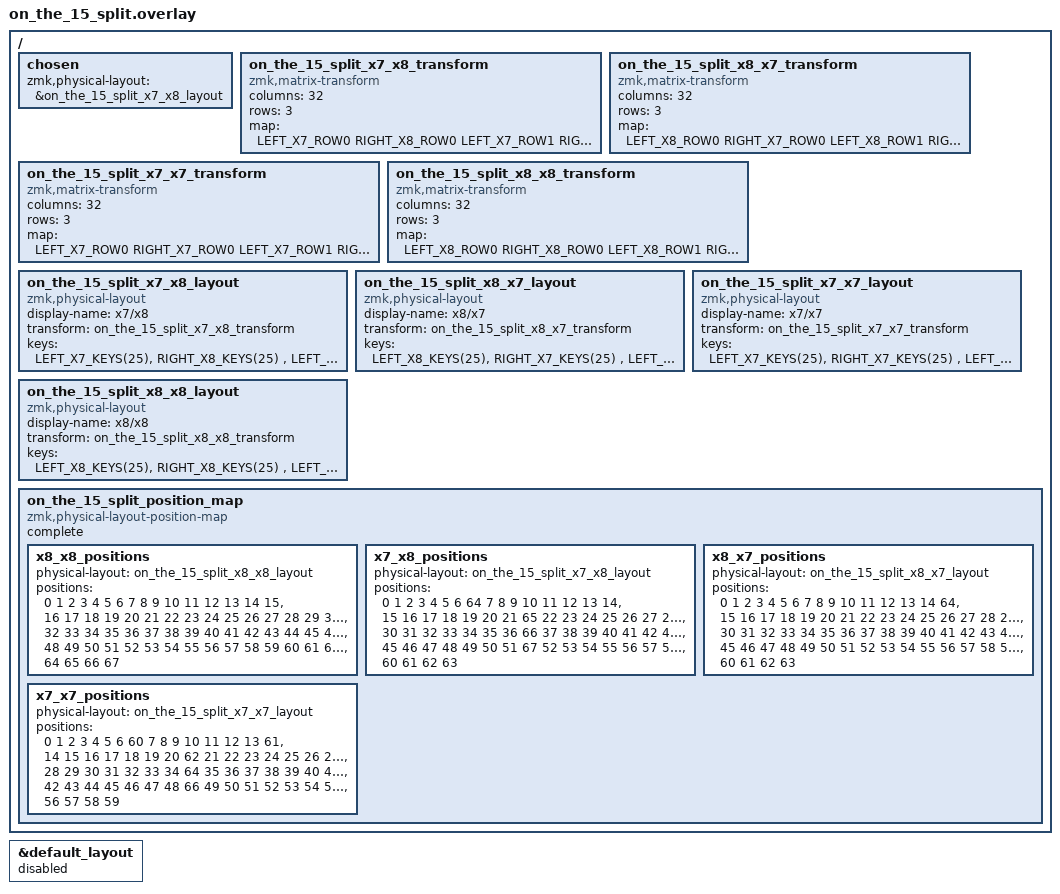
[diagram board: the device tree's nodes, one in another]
/* Studio physical layouts for every x7/x8 split combination. */

#include <dt-bindings/zmk/matrix_transform.h>
#include <physical_layouts.dtsi>

#define LEFT_X7_ROW0 RC(0,0) RC(0,1) RC(0,2) RC(0,3) RC(0,4) RC(0,5) RC(0,6)
#define LEFT_X8_ROW0 LEFT_X7_ROW0 RC(0,7)
#define LEFT_X7_ROW1 RC(1,0) RC(1,1) RC(1,2) RC(1,3) RC(1,4) RC(1,5) RC(1,6)
#define LEFT_X8_ROW1 LEFT_X7_ROW1 RC(1,7)
#define LEFT_X7_ROW2 RC(0,8) RC(0,9) RC(0,10) RC(0,11) RC(0,12) RC(0,13) RC(0,14)
#define LEFT_X8_ROW2 LEFT_X7_ROW2 RC(0,15)
#define LEFT_X7_ROW3 RC(1,8) RC(1,9) RC(1,10) RC(1,11) RC(1,12) RC(1,13) RC(1,14)
#define LEFT_X8_ROW3 LEFT_X7_ROW3 RC(1,15)

#define RIGHT_X7_ROW0 RC(0,16) RC(0,17) RC(0,18) RC(0,19) RC(0,20) RC(0,21) RC(0,22)
#define RIGHT_X8_ROW0 RIGHT_X7_ROW0 RC(0,23)
#define RIGHT_X7_ROW1 RC(1,16) RC(1,17) RC(1,18) RC(1,19) RC(1,20) RC(1,21) RC(1,22)
#define RIGHT_X8_ROW1 RIGHT_X7_ROW1 RC(1,23)
#define RIGHT_X7_ROW2 RC(0,24) RC(0,25) RC(0,26) RC(0,27) RC(0,28) RC(0,29) RC(0,30)
#define RIGHT_X8_ROW2 RIGHT_X7_ROW2 RC(0,31)
#define RIGHT_X7_ROW3 RC(1,24) RC(1,25) RC(1,26) RC(1,27) RC(1,28) RC(1,29) RC(1,30)
#define RIGHT_X8_ROW3 RIGHT_X7_ROW3 RC(1,31)

#define SPLIT_SIDE_KEYS RC(2,7) RC(2,0) RC(2,23) RC(2,16)

#define KEY_AT(x, y) <&key_physical_attrs 100 100 x y 0 0 0>
#define KEY_ROT(x, y, rot, rx, ry) <&key_physical_attrs 100 100 x y rot rx ry>

#define LEFT_X7_KEYS(y) \
    KEY_AT(125, y), KEY_AT(225, y), KEY_AT(325, y), KEY_AT(425, y), \
    KEY_AT(525, y), KEY_AT(625, y), KEY_AT(725, y)
#define LEFT_X8_KEYS(y) LEFT_X7_KEYS(y), KEY_AT(825, y)
#define RIGHT_X7_KEYS(y) \
    KEY_AT(1275, y), KEY_AT(1375, y), KEY_AT(1475, y), KEY_AT(1575, y), \
    KEY_AT(1675, y), KEY_AT(1775, y), KEY_AT(1875, y)
#define RIGHT_X8_KEYS(y) RIGHT_X7_KEYS(y), KEY_AT(1975, y)

#define LEFT_X7_SIDE_KEYS KEY_ROT(850, 0, 1500, 850, 50), KEY_ROT(0, 0, (-1500), 100, 50)
#define LEFT_X8_SIDE_KEYS KEY_ROT(950, 0, 1500, 950, 50), KEY_ROT(0, 0, (-1500), 100, 50)
#define RIGHT_X7_SIDE_KEYS KEY_ROT(2000, 0, 1500, 2000, 50), KEY_ROT(1150, 0, (-1500), 1250, 50)
#define RIGHT_X8_SIDE_KEYS KEY_ROT(2100, 0, 1500, 2100, 50), KEY_ROT(1150, 0, (-1500), 1250, 50)

&default_layout {
    status = "disabled";
};

/ {
    chosen {
        zmk,physical-layout = &on_the_15_split_x7_x8_layout;
    };

    on_the_15_split_x7_x8_transform: on_the_15_split_x7_x8_transform {
        compatible = "zmk,matrix-transform";
        columns = <32>;
        rows = <3>;
        map = <
LEFT_X7_ROW0 RIGHT_X8_ROW0
LEFT_X7_ROW1 RIGHT_X8_ROW1
LEFT_X7_ROW2 RIGHT_X8_ROW2
LEFT_X7_ROW3 RIGHT_X8_ROW3
SPLIT_SIDE_KEYS
        >;
    };

    on_the_15_split_x8_x7_transform: on_the_15_split_x8_x7_transform {
        compatible = "zmk,matrix-transform";
        columns = <32>;
        rows = <3>;
        map = <
LEFT_X8_ROW0 RIGHT_X7_ROW0
LEFT_X8_ROW1 RIGHT_X7_ROW1
LEFT_X8_ROW2 RIGHT_X7_ROW2
LEFT_X8_ROW3 RIGHT_X7_ROW3
SPLIT_SIDE_KEYS
        >;
    };

    on_the_15_split_x7_x7_transform: on_the_15_split_x7_x7_transform {
        compatible = "zmk,matrix-transform";
        columns = <32>;
        rows = <3>;
        map = <
LEFT_X7_ROW0 RIGHT_X7_ROW0
LEFT_X7_ROW1 RIGHT_X7_ROW1
LEFT_X7_ROW2 RIGHT_X7_ROW2
LEFT_X7_ROW3 RIGHT_X7_ROW3
SPLIT_SIDE_KEYS
        >;
    };

    on_the_15_split_x8_x8_transform: on_the_15_split_x8_x8_transform {
        compatible = "zmk,matrix-transform";
        columns = <32>;
        rows = <3>;
        map = <
LEFT_X8_ROW0 RIGHT_X8_ROW0
LEFT_X8_ROW1 RIGHT_X8_ROW1
LEFT_X8_ROW2 RIGHT_X8_ROW2
LEFT_X8_ROW3 RIGHT_X8_ROW3
SPLIT_SIDE_KEYS
        >;
    };

    on_the_15_split_x7_x8_layout: on_the_15_split_x7_x8_layout {
        compatible = "zmk,physical-layout";
        display-name = "x7/x8";
        transform = <&on_the_15_split_x7_x8_transform>;
        keys
            = LEFT_X7_KEYS(25), RIGHT_X8_KEYS(25)
            , LEFT_X7_KEYS(125), RIGHT_X8_KEYS(125)
            , LEFT_X7_KEYS(225), RIGHT_X8_KEYS(225)
            , LEFT_X7_KEYS(325), RIGHT_X8_KEYS(325)
            , LEFT_X7_SIDE_KEYS, RIGHT_X8_SIDE_KEYS
            ;
    };

    on_the_15_split_x8_x7_layout: on_the_15_split_x8_x7_layout {
        compatible = "zmk,physical-layout";
        display-name = "x8/x7";
        transform = <&on_the_15_split_x8_x7_transform>;
        keys
            = LEFT_X8_KEYS(25), RIGHT_X7_KEYS(25)
            , LEFT_X8_KEYS(125), RIGHT_X7_KEYS(125)
            , LEFT_X8_KEYS(225), RIGHT_X7_KEYS(225)
            , LEFT_X8_KEYS(325), RIGHT_X7_KEYS(325)
            , LEFT_X8_SIDE_KEYS, RIGHT_X7_SIDE_KEYS
            ;
    };

    on_the_15_split_x7_x7_layout: on_the_15_split_x7_x7_layout {
        compatible = "zmk,physical-layout";
        display-name = "x7/x7";
        transform = <&on_the_15_split_x7_x7_transform>;
        keys
            = LEFT_X7_KEYS(25), RIGHT_X7_KEYS(25)
            , LEFT_X7_KEYS(125), RIGHT_X7_KEYS(125)
            , LEFT_X7_KEYS(225), RIGHT_X7_KEYS(225)
            , LEFT_X7_KEYS(325), RIGHT_X7_KEYS(325)
            , LEFT_X7_SIDE_KEYS, RIGHT_X7_SIDE_KEYS
            ;
    };

    on_the_15_split_x8_x8_layout: on_the_15_split_x8_x8_layout {
        compatible = "zmk,physical-layout";
        display-name = "x8/x8";
        transform = <&on_the_15_split_x8_x8_transform>;
        keys
            = LEFT_X8_KEYS(25), RIGHT_X8_KEYS(25)
            , LEFT_X8_KEYS(125), RIGHT_X8_KEYS(125)
            , LEFT_X8_KEYS(225), RIGHT_X8_KEYS(225)
            , LEFT_X8_KEYS(325), RIGHT_X8_KEYS(325)
            , LEFT_X8_SIDE_KEYS, RIGHT_X8_SIDE_KEYS
            ;
    };

    on_the_15_split_position_map: on_the_15_split_position_map {
        compatible = "zmk,physical-layout-position-map";
        complete;

        x8_x8_positions {
            physical-layout = <&on_the_15_split_x8_x8_layout>;
            positions
                = < 0  1  2  3  4  5  6  7   8  9 10 11 12 13 14 15>
                , <16 17 18 19 20 21 22 23  24 25 26 27 28 29 30 31>
                , <32 33 34 35 36 37 38 39  40 41 42 43 44 45 46 47>
                , <48 49 50 51 52 53 54 55  56 57 58 59 60 61 62 63>
                , <64 65 66 67>;
        };

        x7_x8_positions {
            physical-layout = <&on_the_15_split_x7_x8_layout>;
            positions
                = < 0  1  2  3  4  5  6 64   7  8  9 10 11 12 13 14>
                , <15 16 17 18 19 20 21 65  22 23 24 25 26 27 28 29>
                , <30 31 32 33 34 35 36 66  37 38 39 40 41 42 43 44>
                , <45 46 47 48 49 50 51 67  52 53 54 55 56 57 58 59>
                , <60 61 62 63>;
        };

        x8_x7_positions {
            physical-layout = <&on_the_15_split_x8_x7_layout>;
            positions
                = < 0  1  2  3  4  5  6  7   8  9 10 11 12 13 14 64>
                , <15 16 17 18 19 20 21 22  23 24 25 26 27 28 29 65>
                , <30 31 32 33 34 35 36 37  38 39 40 41 42 43 44 66>
                , <45 46 47 48 49 50 51 52  53 54 55 56 57 58 59 67>
                , <60 61 62 63>;
        };

        x7_x7_positions {
            physical-layout = <&on_the_15_split_x7_x7_layout>;
            positions
                = < 0  1  2  3  4  5  6 60   7  8  9 10 11 12 13 61>
                , <14 15 16 17 18 19 20 62  21 22 23 24 25 26 27 63>
                , <28 29 30 31 32 33 34 64  35 36 37 38 39 40 41 65>
                , <42 43 44 45 46 47 48 66  49 50 51 52 53 54 55 67>
                , <56 57 58 59>;
        };
    };
};
